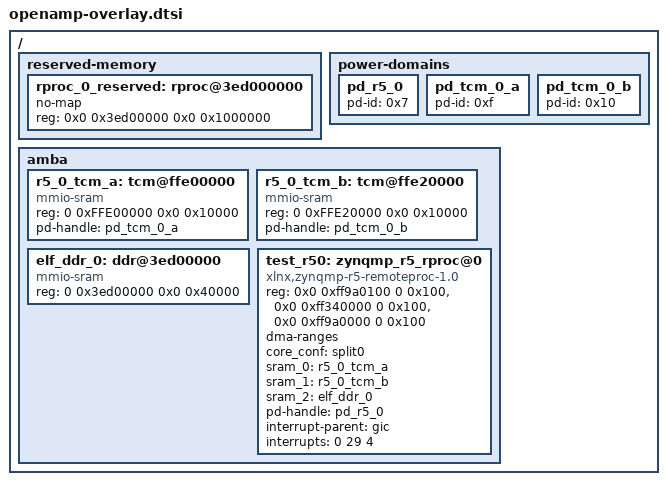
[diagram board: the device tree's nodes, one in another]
/ {
    reserved-memory {
        #address-cells = <2>;
        #size-cells = <2>;
        ranges;
        rproc_0_reserved: rproc@3ed000000 {
            no-map;
            /* DDR memory reserved for RPU firmware.
             * If you want to use predefined shared memory,
             * you should also reserved them here.
             */
            reg = <0x0 0x3ed00000 0x0 0x1000000>;
        };
    };
 
    power-domains {
        /* For TCM memories, you will need specify the power domain
         * IDs. As APU will need to use the power domain ID to request
         * access through PMU FW.
         */
         pd_r5_0: pd_r5_0 {
            #power-domain-cells = <0x0>;
            pd-id = <0x7>;
          };
        pd_tcm_0_a: pd_tcm_0_a {
            #power-domain-cells = <0x0>;
            pd-id = <0xf>;
        };
        pd_tcm_0_b: pd_tcm_0_b {
            #power-domain-cells = <0x0>;
            pd-id = <0x10>;
        };
 
    };
 
    amba {
         /* You will need to specify the firmware memory as "mmio-sram". */
         r5_0_tcm_a: tcm@ffe00000 {
            compatible = "mmio-sram";
            reg = <0 0xFFE00000 0x0 0x10000>;
            pd-handle = <&pd_tcm_0_a>;
        };
        r5_0_tcm_b: tcm@ffe20000 {
            compatible = "mmio-sram";
            reg = <0 0xFFE20000 0x0 0x10000>;
            pd-handle = <&pd_tcm_0_b>;
        };
 
        elf_ddr_0: ddr@3ed00000 {
            compatible = "mmio-sram";
            reg = <0 0x3ed00000 0x0 0x40000>;
        };
 
        test_r50: zynqmp_r5_rproc@0 {
            compatible = "xlnx,zynqmp-r5-remoteproc-1.0";
            reg = <0x0 0xff9a0100 0 0x100>, <0x0 0xff340000 0 0x100>, <0x0 0xff9a0000 0 0x100>;
            reg-names = "rpu_base", "ipi", "rpu_glbl_base";
            dma-ranges;
            core_conf = "split0";
 
            /* Specify the firmware memories here */
            sram_0 = <&r5_0_tcm_a>;
            sram_1 = <&r5_0_tcm_b>;
            sram_2 = <&elf_ddr_0>;
            pd-handle = <&pd_r5_0>;
            interrupt-parent = <&gic>;/*gic*/
            interrupts = <0 29 4>;
 
        } ;
    };
};
